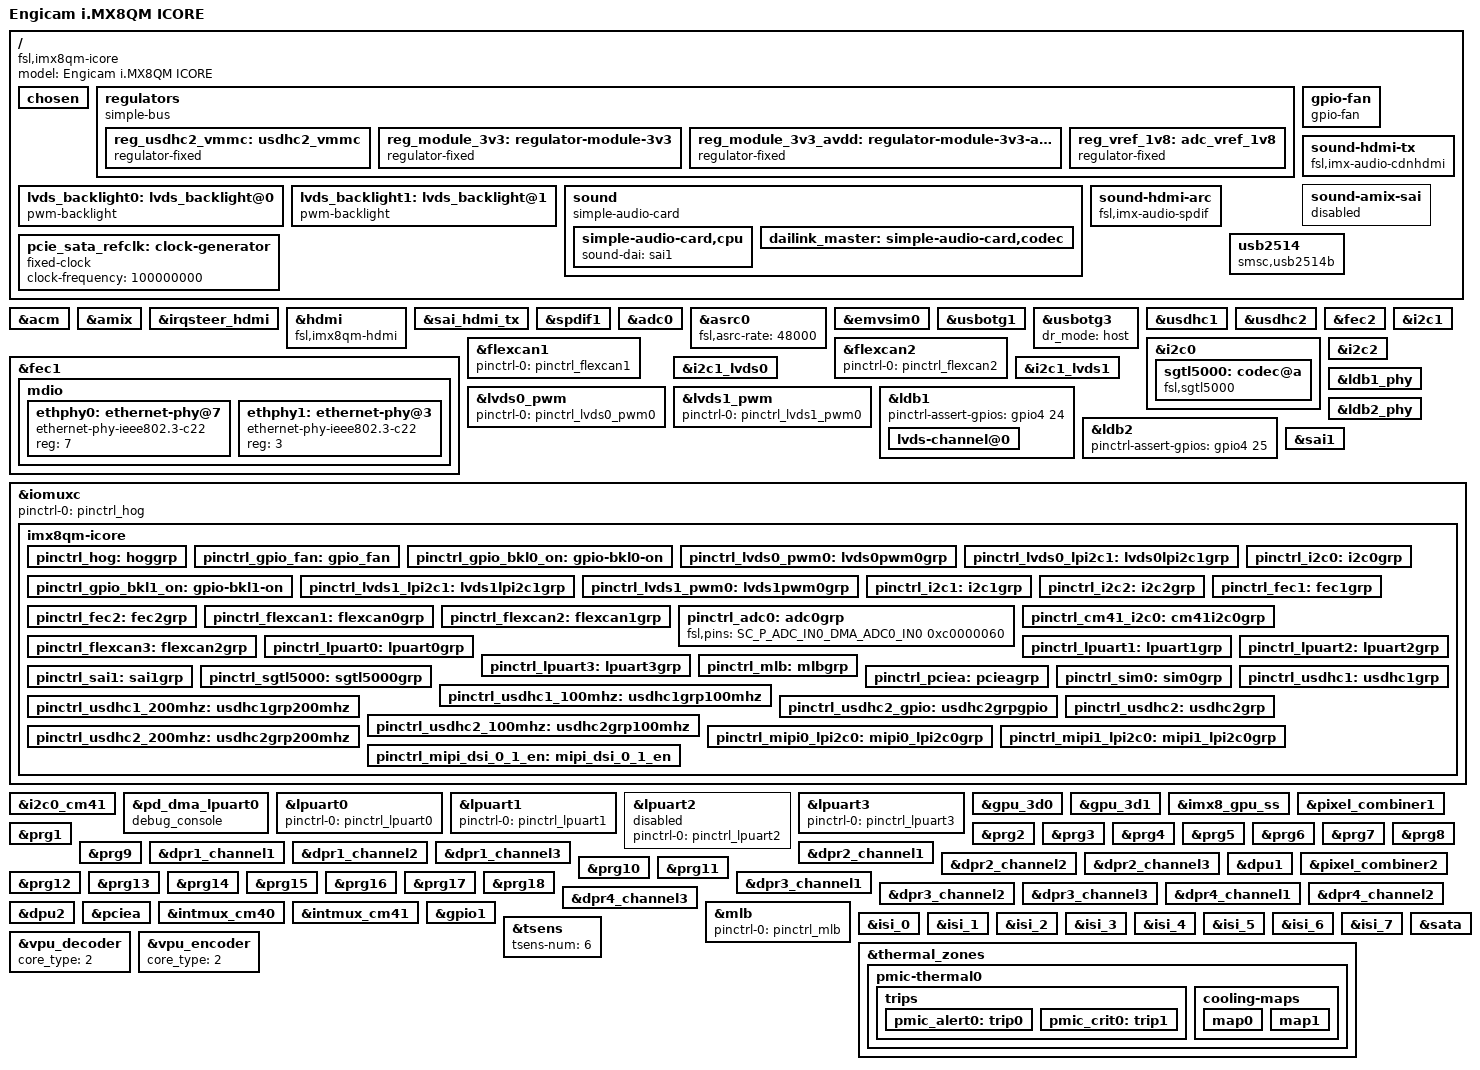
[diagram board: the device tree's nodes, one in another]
/*
 * Copyright 2017-2018 NXP
 *
 * This program is free software; you can redistribute it and/or
 * modify it under the terms of the GNU General Public License
 * as published by the Free Software Foundation; either version 2
 * of the License, or (at your option) any later version.
 *
 * This program is distributed in the hope that it will be useful,
 * but WITHOUT ANY WARRANTY; without even the implied warranty of
 * MERCHANTABILITY or FITNESS FOR A PARTICULAR PURPOSE.  See the
 * GNU General Public License for more details.
 */

#include "../freescale/fsl-imx8qm.dtsi"

/ {
	model = "Engicam i.MX8QM ICORE";
	compatible = "fsl,imx8qm-icore", "fsl,imx8qm";

	chosen {
		bootargs = "console=ttyLP0,115200 earlycon=lpuart32,0x5a060000,115200";
		stdout-path = &lpuart0;
	};

	regulators {
		compatible = "simple-bus";
		#address-cells = <1>;
		#size-cells = <0>;

		reg_usdhc2_vmmc: usdhc2_vmmc {
			compatible = "regulator-fixed";
			regulator-name = "sw-3p3-sd1";
			regulator-min-microvolt = <3300000>;
			regulator-max-microvolt = <3300000>;
		};

		reg_module_3v3: regulator-module-3v3 {
			compatible = "regulator-fixed";
			regulator-name = "+V3.3";
			regulator-min-microvolt = <3300000>;
			regulator-max-microvolt = <3300000>;
		};

		reg_module_3v3_avdd: regulator-module-3v3-avdd {
			compatible = "regulator-fixed";
			regulator-name = "+V3.3_AUDIO";
			regulator-min-microvolt = <3300000>;
			regulator-max-microvolt = <3300000>;
		};

		reg_vref_1v8: adc_vref_1v8 {
			compatible = "regulator-fixed";
			regulator-name = "vref_1v8";
			regulator-min-microvolt = <1800000>;
			regulator-max-microvolt = <1800000>;
		};
	};

	lvds_backlight0: lvds_backlight@0 {
		compatible = "pwm-backlight";
		/* BKL0_ON
		pinctrl-0 = <&pinctrl_gpio_bkl0_on>;
		enable-gpios = <&gpio4 24 GPIO_ACTIVE_HIGH>;  */
		pwms = <&lvds0_pwm 0 100000 0>;
		brightness-levels = < 0  1  2  3  4  5  6  7  8  9
				     10 11 12 13 14 15 16 17 18 19
				     20 21 22 23 24 25 26 27 28 29
				     30 31 32 33 34 35 36 37 38 39
				     40 41 42 43 44 45 46 47 48 49
				     50 51 52 53 54 55 56 57 58 59
				     60 61 62 63 64 65 66 67 68 69
				     70 71 72 73 74 75 76 77 78 79
				     80 81 82 83 84 85 86 87 88 89
				     90 91 92 93 94 95 96 97 98 99
				    100>;
		default-brightness-level = <80>;
	};

	lvds_backlight1: lvds_backlight@1 {
		compatible = "pwm-backlight";
 		/* BKL1_ON 
		pinctrl-0 = <&pinctrl_gpio_bkl1_on>;
		enable-gpios = <&gpio4 25 GPIO_ACTIVE_HIGH>;
		*/
		pwms = <&lvds1_pwm 0 100000 0>;
		
		brightness-levels = < 0  1  2  3  4  5  6  7  8  9
				     10 11 12 13 14 15 16 17 18 19
				     20 21 22 23 24 25 26 27 28 29
				     30 31 32 33 34 35 36 37 38 39
				     40 41 42 43 44 45 46 47 48 49
				     50 51 52 53 54 55 56 57 58 59
				     60 61 62 63 64 65 66 67 68 69
				     70 71 72 73 74 75 76 77 78 79
				     80 81 82 83 84 85 86 87 88 89
				     90 91 92 93 94 95 96 97 98 99
				    100>;
		default-brightness-level = <80>;
	};

	gpio-fan {
		compatible = "gpio-fan";
		pinctrl-names = "default";
		pinctrl-0 = <&pinctrl_gpio_fan>;
		gpios = <&gpio4 26 GPIO_ACTIVE_HIGH>;
		gpio-fan,speed-map = < 0 0 3000 1>;
	};

	sound {
		compatible = "simple-audio-card";
		simple-audio-card,bitclock-master = <&dailink_master>;
		simple-audio-card,format = "i2s";
		simple-audio-card,frame-master = <&dailink_master>;
		simple-audio-card,name = "engicam-imx8qm-sgtl5000";

		simple-audio-card,cpu {
			sound-dai = <&sai1>;
		};

		dailink_master: simple-audio-card,codec {
			clocks = <&clk IMX8QM_AUD_MCLKOUT0>;
			sound-dai = <&sgtl5000>;
		};
	};

	sound-hdmi-tx {
		compatible = "fsl,imx-audio-cdnhdmi";
		model = "imx-audio-hdmi-tx";
		audio-cpu = <&sai_hdmi_tx>;
		protocol = <1>;
		hdmi-out;
	};

	sound-amix-sai {
		status = "disabled";
	};

	sound-hdmi-arc {
		compatible = "fsl,imx-audio-spdif";
		model = "imx-hdmi-arc";
		spdif-controller = <&spdif1>;
		spdif-in;
		spdif-out;
	};

	pcie_sata_refclk: clock-generator {
		compatible = "fixed-clock";
		#clock-cells = <0>;
		clock-frequency = <100000000>;
	};

	usb2514: usb2514 {
		compatible = "smsc,usb2514b";
		reset-gpios = <&gpio4 3 GPIO_ACTIVE_LOW>;
		initial-mode = <1>;
	};

};

&acm {
	status = "okay";
};

&amix {
	status = "okay";
};

&irqsteer_hdmi {
	status = "okay";
};

&hdmi {
	compatible = "fsl,imx8qm-hdmi";
	assigned-clocks = <&clk IMX8QM_HDMI_PXL_SEL>,
					<&clk IMX8QM_HDMI_PXL_LINK_SEL>,
					<&clk IMX8QM_HDMI_PXL_MUX_SEL>;
	assigned-clock-parents = <&clk IMX8QM_HDMI_AV_PLL_CLK>,
							<&clk IMX8QM_HDMI_AV_PLL_CLK>,
							<&clk IMX8QM_HDMI_AV_PLL_CLK>;
	fsl,cec;
	status = "okay";
};

&sai_hdmi_tx {
	assigned-clocks =<&clk IMX8QM_ACM_HDMI_TX_SAI0_MCLK_SEL>,
			<&clk IMX8QM_AUD_PLL0_DIV>,
			<&clk IMX8QM_AUD_ACM_AUD_PLL_CLK0_DIV>,
			<&clk IMX8QM_AUD_ACM_AUD_REC_CLK0_DIV>,
			<&clk IMX8QM_AUD_SAI_HDMITX0_MCLK>;
	assigned-clock-parents = <&clk IMX8QM_AUD_ACM_AUD_PLL_CLK0_CLK>;
	assigned-clock-rates = <0>, <786432000>, <49152000>, <12288000>, <49152000>;
	fsl,sai-asynchronous;
	status = "okay";
};

&spdif1 {
	assigned-clocks =<&clk IMX8QM_AUD_PLL0_DIV>,
			<&clk IMX8QM_AUD_ACM_AUD_PLL_CLK0_DIV>,
			<&clk IMX8QM_AUD_ACM_AUD_REC_CLK0_DIV>;
	assigned-clock-rates = <786432000>, <49152000>, <12288000>;
	status = "okay";
};

&adc0 {
	pinctrl-names = "default";
	pinctrl-0 = <&pinctrl_adc0>;
	vref-supply = <&reg_vref_1v8>;
	status = "okay";
};

&asrc0 {
	fsl,asrc-rate  = <48000>;
	status = "okay";
};

&emvsim0 {
	pinctrl-names = "default", "sleep";
	pinctrl-0 = <&pinctrl_sim0>;
	pinctrl-1 = <&pinctrl_sim0>;
	status = "okay";
};

#define USB1_HOST
#ifdef USB1_HOST
&usbotg1 {
	dr_mode = "host";
	srp-disable;
	hnp-disable;
	adp-disable;
	disable-over-current;
	status = "okay";
};
#else
&usbotg1 {
	//pinctrl-names = "default";
	//pinctrl-0 = <&pinctrl_usbotg1>;
	srp-disable;
	hnp-disable;
	adp-disable;
	power-polarity-active-high;
	disable-over-current;
	status = "okay";
};
#endif

&usbotg3 {
	dr_mode = "host";
	status = "okay";
};

&usdhc1 {
	pinctrl-names = "default", "state_100mhz", "state_200mhz";
	pinctrl-0 = <&pinctrl_usdhc1>;
	pinctrl-1 = <&pinctrl_usdhc1_100mhz>;
	pinctrl-2 = <&pinctrl_usdhc1_200mhz>;
	bus-width = <8>;
	non-removable;
	status = "okay";
};

&usdhc2 {
	pinctrl-names = "default", "state_100mhz", "state_200mhz";
	pinctrl-0 = <&pinctrl_usdhc2>, <&pinctrl_usdhc2_gpio>;
	pinctrl-1 = <&pinctrl_usdhc2_100mhz>, <&pinctrl_usdhc2_gpio>;
	pinctrl-2 = <&pinctrl_usdhc2_200mhz>, <&pinctrl_usdhc2_gpio>;
	bus-width = <4>;
	cd-gpios = <&gpio5 22 GPIO_ACTIVE_LOW>;
	wp-gpios = <&gpio5 21 GPIO_ACTIVE_HIGH>;
	vmmc-supply = <&reg_usdhc2_vmmc>;
	status = "okay";
};

&fec1 {
	pinctrl-names = "default";
	pinctrl-0 = <&pinctrl_fec1>;
	phy-mode = "rgmii-id";
	phy-handle = <&ethphy0>;
	phy-reset-gpios = <&gpio1 28 GPIO_ACTIVE_LOW>;
	phy-reset-duration = <50>;
	//reset-gpio = <&gpio1 28 GPIO_ACTIVE_HIGH>;
	fsl,magic-packet;
	//fsl,rgmii_rxc_dly;
	status = "okay";

	mdio {
		#address-cells = <1>;
		#size-cells = <0>;

		ethphy0: ethernet-phy@7 {
			compatible = "ethernet-phy-ieee802.3-c22";
			reg = <7>;
		};

		ethphy1: ethernet-phy@3 {
			compatible = "ethernet-phy-ieee802.3-c22";
			reg = <3>;
		};
	};
};

&fec2 {
	pinctrl-names = "default";
	pinctrl-0 = <&pinctrl_fec2>;
	phy-mode = "rgmii-id";
	phy-handle = <&ethphy1>;
	phy-reset-gpios = <&gpio1 26 GPIO_ACTIVE_LOW>;
	phy-reset-duration = <50>;
	//reset-gpio = <&gpio1 26 GPIO_ACTIVE_HIGH>;
	fsl,magic-packet;
	//fsl,rgmii_rxc_dly;
	status = "okay";
};

&flexcan1 {
	pinctrl-names = "default";
	pinctrl-0 = <&pinctrl_flexcan1>;
	status = "okay";
};

&flexcan2 {
	pinctrl-names = "default";
	pinctrl-0 = <&pinctrl_flexcan2>;
	status = "okay";
};

&i2c0 {
	#address-cells = <1>;
	#size-cells = <0>;
	clock-frequency = <100000>;
	pinctrl-names = "default";
	pinctrl-0 = <&pinctrl_i2c0>;
	status = "okay";

	/* SGTL5000 */
	sgtl5000: codec@a {
		compatible = "fsl,sgtl5000";
		pinctrl-names = "default";
		pinctrl-0 = <&pinctrl_sgtl5000>;
		#sound-dai-cells = <0>;
		assigned-clocks = <&clk IMX8QM_AUD_PLL0_DIV>,
				  <&clk IMX8QM_AUD_ACM_AUD_PLL_CLK0_DIV>,
				  <&clk IMX8QM_AUD_ACM_AUD_REC_CLK0_DIV>,
				  <&clk IMX8QM_AUD_MCLKOUT0>;
		assigned-clock-rates = <786432000>, <49152000>, <12288000>, <12288000>;
		clocks = <&clk IMX8QM_AUD_MCLKOUT0>;
		power-domains = <&pd_mclk_out0>;
		reg = <0x0a>;
		VDDA-supply = <&reg_module_3v3_avdd>;
		VDDD-supply = <&reg_vref_1v8>;
		VDDIO-supply = <&reg_module_3v3>;
	};
};

&i2c1 {
	#address-cells = <1>;
	#size-cells = <0>;
	clock-frequency = <100000>;
	pinctrl-names = "default";
	pinctrl-0 = <&pinctrl_i2c1>;
	status = "okay";
};

&i2c2 {
	pinctrl-names = "default";
	pinctrl-0 = <&pinctrl_i2c2>;
	#address-cells = <1>;
	#size-cells = <0>;
	clock-frequency = <100000>;
	status = "okay";
};

&lvds0_pwm {
	pinctrl-names = "default";
	pinctrl-0 = <&pinctrl_lvds0_pwm0>;
	status = "okay";
};

&i2c1_lvds0 {
	#address-cells = <1>;
	#size-cells = <0>;
	pinctrl-names = "default";
	pinctrl-0 = <&pinctrl_lvds0_lpi2c1>;
	clock-frequency = <100000>;
	status = "okay";
};

&i2c1_lvds1 {
	#address-cells = <1>;
	#size-cells = <0>;
	pinctrl-names = "default";
	pinctrl-0 = <&pinctrl_lvds1_lpi2c1>;
	clock-frequency = <100000>;
	status = "okay";
};

&lvds1_pwm {
	pinctrl-names = "default";
	pinctrl-0 = <&pinctrl_lvds1_pwm0>;
	status = "okay";
};

&ldb1_phy {
	status = "okay";
};

&ldb1 {
	status = "okay";
	pinctrl-assert-gpios = <&gpio4 24 GPIO_ACTIVE_HIGH>;

	lvds-channel@0 {
		fsl,data-mapping = "jeida";
		fsl,data-width = <24>;
		status = "okay";
	};
};

&ldb2_phy {
	status = "okay";
};

&ldb2 {
	status = "okay";
	pinctrl-assert-gpios = <&gpio4 25 GPIO_ACTIVE_HIGH>;

};

&sai1 {
	assigned-clocks = <&clk IMX8QM_AUD_PLL0_DIV>,
			  <&clk IMX8QM_AUD_ACM_AUD_PLL_CLK0_DIV>,
			  <&clk IMX8QM_AUD_ACM_AUD_REC_CLK0_DIV>,
			  <&clk IMX8QM_AUD_SAI_1_MCLK>;
	assigned-clock-rates = <786432000>, <49152000>, <12288000>, <49152000>;
	#sound-dai-cells = <0>;
	pinctrl-names = "default";
	pinctrl-0 = <&pinctrl_sai1>;
	status = "okay";
};


&iomuxc {
	pinctrl-names = "default";
	pinctrl-0 = <&pinctrl_hog>;

	imx8qm-icore {
		pinctrl_hog: hoggrp {
			fsl,pins = <
				SC_P_QSPI1A_DATA3_LSIO_GPIO4_IO23           0x0600004c
				SC_P_QSPI1A_DATA2_LSIO_GPIO4_IO24	        0x06000021
				SC_P_QSPI1A_DATA1_LSIO_GPIO4_IO25	        0x0600004c
				SC_P_SCU_GPIO0_03_LSIO_GPIO0_IO31	        0x0600004c
				SC_P_USB_SS3_TC0_LSIO_GPIO4_IO03	        0x06000048   
			>;
		};

		pinctrl_gpio_fan: gpio_fan {
			fsl,pins = <
				SC_P_QSPI1A_DATA0_LSIO_GPIO4_IO26	        0x0600004c
			>;
		};

		/* BKL0_ON */
		pinctrl_gpio_bkl0_on: gpio-bkl0-on {
			fsl,pins = <
				SC_P_QSPI1A_DATA2_LSIO_GPIO4_IO24	        0x06000021
			>;
		};

		pinctrl_lvds0_pwm0: lvds0pwm0grp {
			fsl,pins = <
				SC_P_LVDS0_GPIO00_LVDS0_PWM0_OUT	        0x00000020
			>;
		};


		pinctrl_lvds0_lpi2c1: lvds0lpi2c1grp {
			fsl,pins = <
				SC_P_LVDS0_I2C1_SCL_LVDS0_I2C1_SCL	        0xc600004c
				SC_P_LVDS0_I2C1_SDA_LVDS0_I2C1_SDA	        0xc600004c
			>;
		};


		/* BKL1_ON */
		pinctrl_gpio_bkl1_on: gpio-bkl1-on {
			fsl,pins = <
				SC_P_LVDS0_GPIO00_LSIO_GPIO1_IO04	        0x00000021
			>;
		};

		pinctrl_lvds1_lpi2c1: lvds1lpi2c1grp {
			fsl,pins = <
				SC_P_LVDS1_I2C1_SCL_LVDS1_I2C1_SCL	        0xc600004c
				SC_P_LVDS1_I2C1_SDA_LVDS1_I2C1_SDA	        0xc600004c
			>;
		};

		pinctrl_lvds1_pwm0: lvds1pwm0grp {
			fsl,pins = <
				SC_P_LVDS1_GPIO00_LVDS1_PWM0_OUT	        0x00000020
			>;
		};

		pinctrl_i2c0: i2c0grp {
			fsl,pins = <
				SC_P_HDMI_TX0_TS_SCL_DMA_I2C0_SCL	        0x04000022
				SC_P_HDMI_TX0_TS_SDA_DMA_I2C0_SDA	        0x04000022
			>;
		};

		pinctrl_i2c1: i2c1grp {
			fsl,pins = <
				SC_P_GPT0_CLK_DMA_I2C1_SCL                      0x04000020
				SC_P_GPT0_CAPTURE_DMA_I2C1_SDA                  0x04000020
			>;
		};

		pinctrl_i2c2: i2c2grp {
			fsl,pins = <
				SC_P_GPT1_CLK_DMA_I2C2_SCL		        0x04000020
				SC_P_GPT1_CAPTURE_DMA_I2C2_SDA		        0x04000020
			>;
		};

		pinctrl_fec1: fec1grp {
			fsl,pins = <
				SC_P_COMP_CTL_GPIO_1V8_3V3_ENET_ENETB_PAD	0x000014a0
				SC_P_ENET0_MDC_CONN_ENET0_MDC			0x06000020
				SC_P_ENET0_MDIO_CONN_ENET0_MDIO			0x06000020
				SC_P_ENET0_RGMII_TX_CTL_CONN_ENET0_RGMII_TX_CTL	0x00000061
				SC_P_ENET0_RGMII_TXC_CONN_ENET0_RGMII_TXC	0x00000061
				SC_P_ENET0_RGMII_TXD0_CONN_ENET0_RGMII_TXD0	0x00000061
				SC_P_ENET0_RGMII_TXD1_CONN_ENET0_RGMII_TXD1	0x00000061
				SC_P_ENET0_RGMII_TXD2_CONN_ENET0_RGMII_TXD2	0x00000061
				SC_P_ENET0_RGMII_TXD3_CONN_ENET0_RGMII_TXD3	0x00000061
				SC_P_ENET0_RGMII_RXC_CONN_ENET0_RGMII_RXC	0x00000061
				SC_P_ENET0_RGMII_RX_CTL_CONN_ENET0_RGMII_RX_CTL	0x00000061
				SC_P_ENET0_RGMII_RXD0_CONN_ENET0_RGMII_RXD0	0x00000061
				SC_P_ENET0_RGMII_RXD1_CONN_ENET0_RGMII_RXD1	0x00000061
				SC_P_ENET0_RGMII_RXD2_CONN_ENET0_RGMII_RXD2	0x00000061
				SC_P_ENET0_RGMII_RXD3_CONN_ENET0_RGMII_RXD3	0x00000061
				SC_P_MIPI_CSI0_GPIO0_01_LSIO_GPIO1_IO28         0x00000021
			>;
		};

		pinctrl_fec2: fec2grp {
			fsl,pins = <
				SC_P_COMP_CTL_GPIO_1V8_3V3_ENET_ENETA_PAD	0x000014a0
				SC_P_ENET1_RGMII_TX_CTL_CONN_ENET1_RGMII_TX_CTL	0x00000060
				SC_P_ENET1_RGMII_TXC_CONN_ENET1_RGMII_TXC	0x00000060
				SC_P_ENET1_RGMII_TXD0_CONN_ENET1_RGMII_TXD0	0x00000060
				SC_P_ENET1_RGMII_TXD1_CONN_ENET1_RGMII_TXD1	0x00000060
				SC_P_ENET1_RGMII_TXD2_CONN_ENET1_RGMII_TXD2	0x00000060
				SC_P_ENET1_RGMII_TXD3_CONN_ENET1_RGMII_TXD3	0x00000060
				SC_P_ENET1_RGMII_RXC_CONN_ENET1_RGMII_RXC	0x00000060
				SC_P_ENET1_RGMII_RX_CTL_CONN_ENET1_RGMII_RX_CTL	0x00000060
				SC_P_ENET1_RGMII_RXD0_CONN_ENET1_RGMII_RXD0	0x00000060
				SC_P_ENET1_RGMII_RXD1_CONN_ENET1_RGMII_RXD1	0x00000060
				SC_P_ENET1_RGMII_RXD2_CONN_ENET1_RGMII_RXD2	0x00000060
				SC_P_ENET1_RGMII_RXD3_CONN_ENET1_RGMII_RXD3	0x00000060
				SC_P_MIPI_CSI0_I2C0_SDA_LSIO_GPIO1_IO26         0x00000021 
			>;
		};

		pinctrl_flexcan1: flexcan0grp {
			fsl,pins = <
				SC_P_FLEXCAN0_TX_DMA_FLEXCAN0_TX                0x00000021 
				SC_P_FLEXCAN0_RX_DMA_FLEXCAN0_RX                0x00000021 
			>;
		};

		pinctrl_flexcan2: flexcan1grp {
			fsl,pins = <
				SC_P_FLEXCAN1_TX_DMA_FLEXCAN1_TX                0x00000021 
				SC_P_FLEXCAN1_RX_DMA_FLEXCAN1_RX                0x00000021 
			>;
		};

		pinctrl_adc0: adc0grp {
			fsl,pins = <
				SC_P_ADC_IN0_DMA_ADC0_IN0		        0xc0000060
			>;
		};

		pinctrl_cm41_i2c0: cm41i2c0grp {
			fsl,pins = <
				SC_P_M41_I2C0_SCL_M41_I2C0_SCL                  0x0600004c
				SC_P_M41_I2C0_SDA_M41_I2C0_SDA                  0x0600004c
			>;
		};

		pinctrl_flexcan3: flexcan2grp {
			fsl,pins = <
				SC_P_FLEXCAN2_TX_DMA_FLEXCAN2_TX                0x00000021 
				SC_P_FLEXCAN2_RX_DMA_FLEXCAN2_RX                0x00000021 
			>;
		};

		pinctrl_lpuart0: lpuart0grp {
			fsl,pins = <
				SC_P_UART0_RX_DMA_UART0_RX		        0x06000020
				SC_P_UART0_TX_DMA_UART0_TX		        0x06000020
			>;
		};

		pinctrl_lpuart1: lpuart1grp {
			fsl,pins = <
				SC_P_UART1_RX_DMA_UART1_RX		        0x06000020
				SC_P_UART1_TX_DMA_UART1_TX		        0x06000020
				SC_P_UART1_CTS_B_DMA_UART1_CTS_B 	        0x06000020
				SC_P_UART1_RTS_B_DMA_UART1_RTS_B	        0x06000020
			>;
		};

		pinctrl_lpuart2: lpuart2grp {
			fsl,pins = <
				SC_P_UART0_RTS_B_DMA_UART2_RX		        0x06000020
				SC_P_UART0_CTS_B_DMA_UART2_TX		        0x06000020
			>;
		};

		pinctrl_lpuart3: lpuart3grp {
			fsl,pins = <
				SC_P_M41_GPIO0_00_DMA_UART3_RX		        0x06000020
				SC_P_M41_GPIO0_01_DMA_UART3_TX		        0x06000020
			>;
		};

		pinctrl_mlb: mlbgrp {
			fsl,pins = <
				SC_P_MLB_SIG_CONN_MLB_SIG                       0x21
				SC_P_MLB_CLK_CONN_MLB_CLK                       0x21
				SC_P_MLB_DATA_CONN_MLB_DATA                     0x21
			>;
		};

		pinctrl_sai1: sai1grp {
			fsl,pins = <
				SC_P_SAI1_RXD_AUD_SAI1_RXD		        0x06000040
				SC_P_SAI1_RXC_AUD_SAI1_RXC		        0x06000040
				SC_P_SAI1_TXD_AUD_SAI1_TXD		        0x06000060
				SC_P_SAI1_TXC_AUD_SAI1_TXC		        0x06000040
			>;
		};

		/* On-module I2S SGTL5000 SYS_MCLK */
		pinctrl_sgtl5000: sgtl5000grp {
			fsl,pins = <
				SC_P_MCLK_OUT0_AUD_ACM_MCLK_OUT0	        0xc600004c
			>;
		};

		pinctrl_pciea: pcieagrp{
			fsl,pins = <
				SC_P_PCIE_CTRL0_CLKREQ_B_LSIO_GPIO4_IO27	0x06000021
				SC_P_PCIE_CTRL0_WAKE_B_LSIO_GPIO4_IO28		0x04000021
				SC_P_PCIE_CTRL0_PERST_B_LSIO_GPIO4_IO29		0x06000021
				SC_P_USDHC2_RESET_B_LSIO_GPIO4_IO09		0x06000021
			>;
		};

		pinctrl_sim0: sim0grp {
			fsl,pins = <
				SC_P_SIM0_CLK_DMA_SIM0_CLK			0xc0000021
				SC_P_SIM0_IO_DMA_SIM0_IO			0xc2000021
				SC_P_SIM0_PD_DMA_SIM0_PD			0xc0000021
				SC_P_SIM0_POWER_EN_DMA_SIM0_POWER_EN		0xc0000021
				SC_P_SIM0_RST_DMA_SIM0_RST			0xc0000021
			>;
		};

		pinctrl_usdhc1: usdhc1grp {
			fsl,pins = <
				SC_P_EMMC0_CLK_CONN_EMMC0_CLK			0x06000041
				SC_P_EMMC0_CMD_CONN_EMMC0_CMD			0x00000021
				SC_P_EMMC0_DATA0_CONN_EMMC0_DATA0		0x00000021
				SC_P_EMMC0_DATA1_CONN_EMMC0_DATA1		0x00000021
				SC_P_EMMC0_DATA2_CONN_EMMC0_DATA2		0x00000021
				SC_P_EMMC0_DATA3_CONN_EMMC0_DATA3		0x00000021
				SC_P_EMMC0_DATA4_CONN_EMMC0_DATA4		0x00000021
				SC_P_EMMC0_DATA5_CONN_EMMC0_DATA5		0x00000021
				SC_P_EMMC0_DATA6_CONN_EMMC0_DATA6		0x00000021
				SC_P_EMMC0_DATA7_CONN_EMMC0_DATA7		0x00000021
				SC_P_EMMC0_STROBE_CONN_EMMC0_STROBE		0x00000041
				SC_P_EMMC0_RESET_B_CONN_EMMC0_RESET_B		0x00000021
			>;
		};

		pinctrl_usdhc1_100mhz: usdhc1grp100mhz {
			fsl,pins = <
				SC_P_EMMC0_CLK_CONN_EMMC0_CLK		        0x06000040
				SC_P_EMMC0_CMD_CONN_EMMC0_CMD		        0x00000020
				SC_P_EMMC0_DATA0_CONN_EMMC0_DATA0	        0x00000020
				SC_P_EMMC0_DATA1_CONN_EMMC0_DATA1	        0x00000020
				SC_P_EMMC0_DATA2_CONN_EMMC0_DATA2	        0x00000020
				SC_P_EMMC0_DATA3_CONN_EMMC0_DATA3	        0x00000020
				SC_P_EMMC0_DATA4_CONN_EMMC0_DATA4	        0x00000020
				SC_P_EMMC0_DATA5_CONN_EMMC0_DATA5	        0x00000020
				SC_P_EMMC0_DATA6_CONN_EMMC0_DATA6	        0x00000020
				SC_P_EMMC0_DATA7_CONN_EMMC0_DATA7	        0x00000020
				SC_P_EMMC0_STROBE_CONN_EMMC0_STROBE	        0x00000040
				SC_P_EMMC0_RESET_B_CONN_EMMC0_RESET_B	        0x00000020
			>;
		};

		pinctrl_usdhc1_200mhz: usdhc1grp200mhz {
			fsl,pins = <
				SC_P_EMMC0_CLK_CONN_EMMC0_CLK		        0x06000040
				SC_P_EMMC0_CMD_CONN_EMMC0_CMD		        0x00000020
				SC_P_EMMC0_DATA0_CONN_EMMC0_DATA0	        0x00000020
				SC_P_EMMC0_DATA1_CONN_EMMC0_DATA1	        0x00000020
				SC_P_EMMC0_DATA2_CONN_EMMC0_DATA2	        0x00000020
				SC_P_EMMC0_DATA3_CONN_EMMC0_DATA3	        0x00000020
				SC_P_EMMC0_DATA4_CONN_EMMC0_DATA4	        0x00000020
				SC_P_EMMC0_DATA5_CONN_EMMC0_DATA5	        0x00000020
				SC_P_EMMC0_DATA6_CONN_EMMC0_DATA6	        0x00000020
				SC_P_EMMC0_DATA7_CONN_EMMC0_DATA7	        0x00000020
				SC_P_EMMC0_STROBE_CONN_EMMC0_STROBE	        0x00000040
				SC_P_EMMC0_RESET_B_CONN_EMMC0_RESET_B	        0x00000020
			>;
		};

		pinctrl_usdhc2_gpio: usdhc2grpgpio {
			fsl,pins = <
				SC_P_USDHC1_DATA6_LSIO_GPIO5_IO21	        0x06000021
				SC_P_USDHC1_DATA7_LSIO_GPIO5_IO22	        0x06000021
				SC_P_USDHC1_RESET_B_LSIO_GPIO4_IO07	        0x0000021
			>;
		};

		pinctrl_usdhc2: usdhc2grp {
			fsl,pins = <
				SC_P_USDHC1_CLK_CONN_USDHC1_CLK		        0x06000041
				SC_P_USDHC1_CMD_CONN_USDHC1_CMD		        0x06000021
				SC_P_USDHC1_DATA0_CONN_USDHC1_DATA0	        0x06000021
				SC_P_USDHC1_DATA1_CONN_USDHC1_DATA1	        0x06000021
				SC_P_USDHC1_DATA2_CONN_USDHC1_DATA2	        0x06000021
				SC_P_USDHC1_DATA3_CONN_USDHC1_DATA3	        0x06000021
				SC_P_USDHC1_VSELECT_CONN_USDHC1_VSELECT	        0x06000021
			>;
		};

		pinctrl_usdhc2_100mhz: usdhc2grp100mhz {
			fsl,pins = <
				SC_P_USDHC1_CLK_CONN_USDHC1_CLK		        0x06000040
				SC_P_USDHC1_CMD_CONN_USDHC1_CMD		        0x06000020
				SC_P_USDHC1_DATA0_CONN_USDHC1_DATA0	        0x06000020
				SC_P_USDHC1_DATA1_CONN_USDHC1_DATA1	        0x06000020
				SC_P_USDHC1_DATA2_CONN_USDHC1_DATA2	        0x06000020
				SC_P_USDHC1_DATA3_CONN_USDHC1_DATA3	        0x06000020
				SC_P_USDHC1_VSELECT_CONN_USDHC1_VSELECT	        0x06000020
			>;
		};

		pinctrl_usdhc2_200mhz: usdhc2grp200mhz {
			fsl,pins = <
				SC_P_USDHC1_CLK_CONN_USDHC1_CLK		        0x06000040
				SC_P_USDHC1_CMD_CONN_USDHC1_CMD		        0x06000020
				SC_P_USDHC1_DATA0_CONN_USDHC1_DATA0	        0x06000020
				SC_P_USDHC1_DATA1_CONN_USDHC1_DATA1	        0x06000020
				SC_P_USDHC1_DATA2_CONN_USDHC1_DATA2	        0x06000020
				SC_P_USDHC1_DATA3_CONN_USDHC1_DATA3	        0x06000020
				SC_P_USDHC1_VSELECT_CONN_USDHC1_VSELECT	        0x06000020
			>;
		};

		pinctrl_mipi0_lpi2c0: mipi0_lpi2c0grp {
			fsl,pins = <
				SC_P_MIPI_DSI0_I2C0_SCL_MIPI_DSI0_I2C0_SCL	0xc600004c
				SC_P_MIPI_DSI0_I2C0_SDA_MIPI_DSI0_I2C0_SDA	0xc600004c
				SC_P_MIPI_DSI0_GPIO0_01_LSIO_GPIO1_IO19		0x00000020
			>;
		};

		pinctrl_mipi1_lpi2c0: mipi1_lpi2c0grp {
			fsl,pins = <
				SC_P_MIPI_DSI1_I2C0_SCL_MIPI_DSI1_I2C0_SCL	0xc600004c
				SC_P_MIPI_DSI1_I2C0_SDA_MIPI_DSI1_I2C0_SDA	0xc600004c
				SC_P_MIPI_DSI1_GPIO0_01_LSIO_GPIO1_IO23		0x00000020
			>;
		};

		pinctrl_mipi_dsi_0_1_en: mipi_dsi_0_1_en {
			fsl,pins = <
				SC_P_LVDS0_I2C0_SDA_LSIO_GPIO1_IO07		0x00000021
			>;
		};

	};
};


&i2c0_cm41 {
	#address-cells = <1>;
	#size-cells = <0>;
	clock-frequency = <100000>;
	pinctrl-names = "default";
	pinctrl-0 = <&pinctrl_cm41_i2c0>;
	status = "okay";

};

&pd_dma_lpuart0 {
	debug_console;
};

&lpuart0 { /* console */
	pinctrl-names = "default";
	pinctrl-0 = <&pinctrl_lpuart0>;
	status = "okay";
};

&lpuart1 { /* BT */
	pinctrl-names = "default";
	pinctrl-0 = <&pinctrl_lpuart1>;
	status = "okay";
};

&lpuart2 { /* Dbg console */
	pinctrl-names = "default";
	pinctrl-0 = <&pinctrl_lpuart2>;
	status = "disabled";
};

&lpuart3 { /* MKbus */
	pinctrl-names = "default";
	pinctrl-0 = <&pinctrl_lpuart3>;
	status = "okay";
};

&gpu_3d0 {
        status = "okay";
};

&gpu_3d1 {
        status = "okay";
};

&imx8_gpu_ss {
        status = "okay";
};

&pixel_combiner1 {
	status = "okay";
};

&prg1 {
	status = "okay";
};

&prg2 {
	status = "okay";
};

&prg3 {
	status = "okay";
};

&prg4 {
	status = "okay";
};

&prg5 {
	status = "okay";
};

&prg6 {
	status = "okay";
};

&prg7 {
	status = "okay";
};

&prg8 {
	status = "okay";
};

&prg9 {
	status = "okay";
};

&dpr1_channel1 {
	status = "okay";
};

&dpr1_channel2 {
	status = "okay";
};

&dpr1_channel3 {
	status = "okay";
};

&dpr2_channel1 {
	status = "okay";
};

&dpr2_channel2 {
	status = "okay";
};

&dpr2_channel3 {
	status = "okay";
};

&dpu1 {
	status = "okay";
};

&pixel_combiner2 {
	status = "okay";
};

&prg10 {
	status = "okay";
};

&prg11 {
	status = "okay";
};

&prg12 {
	status = "okay";
};

&prg13 {
	status = "okay";
};

&prg14 {
	status = "okay";
};

&prg15 {
	status = "okay";
};

&prg16 {
	status = "okay";
};

&prg17 {
	status = "okay";
};

&prg18 {
	status = "okay";
};

&dpr3_channel1 {
	status = "okay";
};

&dpr3_channel2 {
	status = "okay";
};

&dpr3_channel3 {
	status = "okay";
};

&dpr4_channel1 {
	status = "okay";
};

&dpr4_channel2 {
	status = "okay";
};

&dpr4_channel3 {
	status = "okay";
};

&dpu2 {
	status = "okay";
};

&pciea{
	ext_osc = <1>;
	pinctrl-names = "default";
	pinctrl-0 = <&pinctrl_pciea>;
	disable-gpio = <&gpio4 9 GPIO_ACTIVE_LOW>;
	reset-gpio = <&gpio4 29 GPIO_ACTIVE_LOW>;
	clkreq-gpio = <&gpio4 27 GPIO_ACTIVE_LOW>;
	//epdev_on-supply = <&epdev_on>;@ked
	status = "okay";
};

&intmux_cm40 {
	status = "okay";
};

&intmux_cm41 {
	status = "okay";
};

/*
&i2c0_mipi_csi0 {
	#address-cells = <1>;
	#size-cells = <0>;
	clock-frequency = <100000>;
	status = "okay";
};

&i2c0_mipi_csi1 {
	#address-cells = <1>;
	#size-cells = <0>;
	clock-frequency = <100000>;
	status = "okay";
};
*/

&mlb {
	pinctrl-names = "default";
	pinctrl-0 = <&pinctrl_mlb>;
	status = "okay";
};

&gpio1 {
	status = "okay";
};


&isi_0 {
	status = "okay";
};

&isi_1 {
	status = "okay";
};

&isi_2 {
	status = "okay";
};

&isi_3 {
	status = "okay";
};

&isi_4 {
	status = "okay";
};

&isi_5 {
	status = "okay";
};

&isi_6 {
	status = "okay";
};

&isi_7 {
	status = "okay";
};

&sata {
	pinctrl-0 = <&pinctrl_pciea>;
	clkreq-gpio = <&gpio4 27 GPIO_ACTIVE_LOW>;
	status = "okay";
};


/*
&i2c0_mipi_dsi0 {
	#address-cells = <1>;
	#size-cells = <0>;
	pinctrl-names = "default";
	pinctrl-0 = <&pinctrl_mipi0_lpi2c0>;
	clock-frequency = <100000>;
	status = "okay";
};

&mipi_dsi_phy1 {
	status = "okay";
};

&mipi_dsi1 {
	pwr-delay = <10>;
	status = "okay";
};

&mipi_dsi_bridge1 {
	status = "okay";
};

&i2c0_mipi_dsi1 {
	#address-cells = <1>;
	#size-cells = <0>;
	pinctrl-names = "default";
	pinctrl-0 = <&pinctrl_mipi1_lpi2c0>;
	clock-frequency = <100000>;
	status = "okay";
};

&mipi_dsi_phy2 {
	status = "okay";
};

&mipi_dsi2 {
	pwr-delay = <10>;
	status = "okay";
};

&mipi_dsi_bridge2 {
	status = "okay";
};
*/

&tsens {
	tsens-num = <6>;
};

&thermal_zones {
	pmic-thermal0 {
		polling-delay-passive = <250>;
		polling-delay = <2000>;
		thermal-sensors = <&tsens 5>;
		trips {
			pmic_alert0: trip0 {
				temperature = <110000>;
				hysteresis = <2000>;
				type = "passive";
			};
			pmic_crit0: trip1 {
				temperature = <125000>;
				hysteresis = <2000>;
				type = "critical";
			};
		};
		cooling-maps {
			map0 {
				trip = <&pmic_alert0>;
				cooling-device =
				<&A53_0 THERMAL_NO_LIMIT THERMAL_NO_LIMIT>;
			};
			map1 {
				trip = <&pmic_alert0>;
				cooling-device =
				<&A72_0 THERMAL_NO_LIMIT THERMAL_NO_LIMIT>;
			};
		};
	};
};

&vpu_decoder {
	core_type = <2>;
	status = "okay";
};

&vpu_encoder {
	core_type = <2>;
	status = "okay";
};




